# ipro7 register map
Vendor: intelpro; Series: BTBLE
CPU: ipro7, little endian
Registers are 32-bit, read-write, reset 0x0 unless marked. A register's access mark holds for its fields unless they carry their own. Offsets are from the block's base; [hi:lo] are bit positions; {n}, {i} and the like mark numbered series.

## M154_MEM
Base 0x3C000000
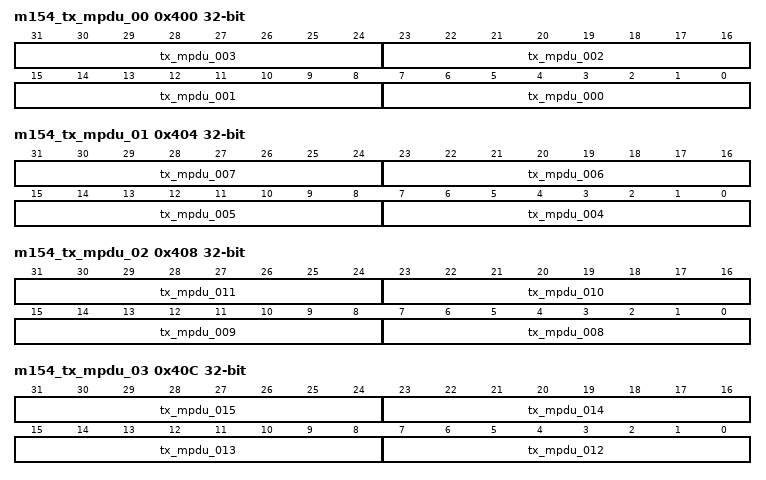
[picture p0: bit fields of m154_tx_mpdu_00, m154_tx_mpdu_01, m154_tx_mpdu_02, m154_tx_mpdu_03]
0x400 m154_tx_mpdu_00 reset not defined
  [8n+7:8n] tx_mpdu_{n:03} ro (n=0..3) — TX MPDU {n}
0x404 m154_tx_mpdu_01 reset not defined
  [8n-25:8n-32] tx_mpdu_{n:03} ro (n=4..7) — TX MPDU {n}
0x408 m154_tx_mpdu_02 reset not defined
  [8n-57:8n-64] tx_mpdu_{n:03} ro (n=8..11) — TX MPDU {n}
0x40C m154_tx_mpdu_03 reset not defined
  [8n-89:8n-96] tx_mpdu_{n:03} ro (n=12..15) — TX MPDU {n}
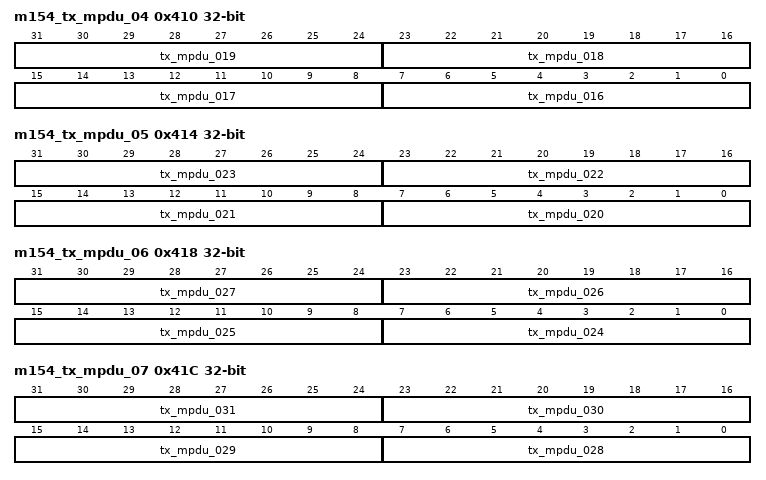
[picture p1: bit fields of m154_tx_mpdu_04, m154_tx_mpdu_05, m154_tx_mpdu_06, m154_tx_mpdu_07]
0x410 m154_tx_mpdu_04 reset not defined
  [8n-121:8n-128] tx_mpdu_{n:03} ro (n=16..19) — TX MPDU {n}
0x414 m154_tx_mpdu_05 reset not defined
  [8n-153:8n-160] tx_mpdu_{n:03} ro (n=20..23) — TX MPDU {n}
0x418 m154_tx_mpdu_06 reset not defined
  [8n-185:8n-192] tx_mpdu_{n:03} ro (n=24..27) — TX MPDU {n}
0x41C m154_tx_mpdu_07 reset not defined
  [8n-217:8n-224] tx_mpdu_{n:03} ro (n=28..31) — TX MPDU {n}
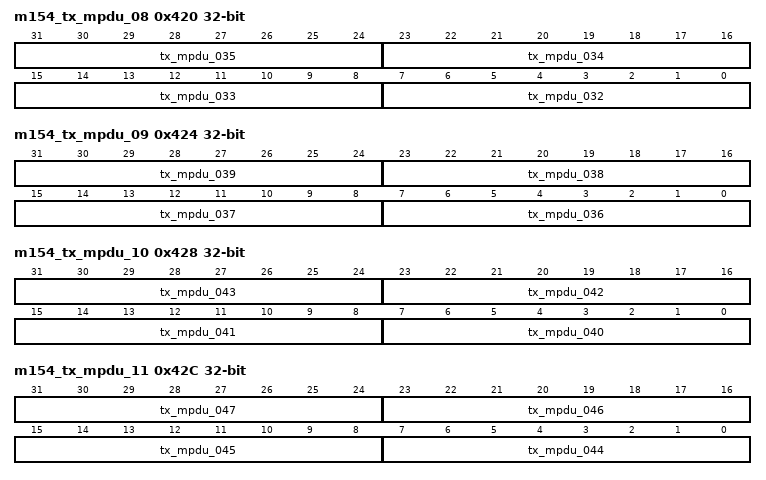
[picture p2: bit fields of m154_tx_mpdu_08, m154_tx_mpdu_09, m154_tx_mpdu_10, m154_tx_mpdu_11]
0x420 m154_tx_mpdu_08 reset not defined
  [8n-249:8n-256] tx_mpdu_{n:03} ro (n=32..35) — TX MPDU {n}
0x424 m154_tx_mpdu_09 reset not defined
  [8n-281:8n-288] tx_mpdu_{n:03} ro (n=36..39) — TX MPDU {n}
0x428 m154_tx_mpdu_10 reset not defined
  [8n-313:8n-320] tx_mpdu_{n:03} ro (n=40..43) — TX MPDU {n}
0x42C m154_tx_mpdu_11 reset not defined
  [8n-345:8n-352] tx_mpdu_{n:03} ro (n=44..47) — TX MPDU {n}
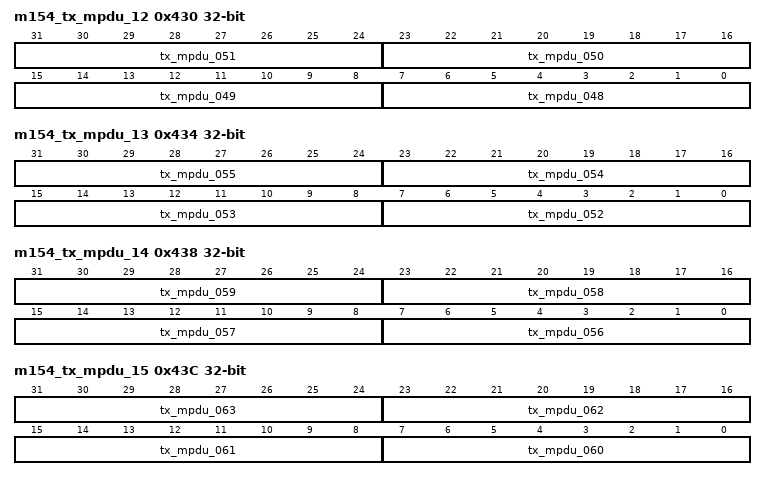
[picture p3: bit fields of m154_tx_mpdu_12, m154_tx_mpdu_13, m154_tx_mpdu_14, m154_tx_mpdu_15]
0x430 m154_tx_mpdu_12 reset not defined
  [8n-377:8n-384] tx_mpdu_{n:03} ro (n=48..51) — TX MPDU {n}
0x434 m154_tx_mpdu_13 reset not defined
  [8n-409:8n-416] tx_mpdu_{n:03} ro (n=52..55) — TX MPDU {n}
0x438 m154_tx_mpdu_14 reset not defined
  [8n-441:8n-448] tx_mpdu_{n:03} ro (n=56..59) — TX MPDU {n}
0x43C m154_tx_mpdu_15 reset not defined
  [8n-473:8n-480] tx_mpdu_{n:03} ro (n=60..63) — TX MPDU {n}
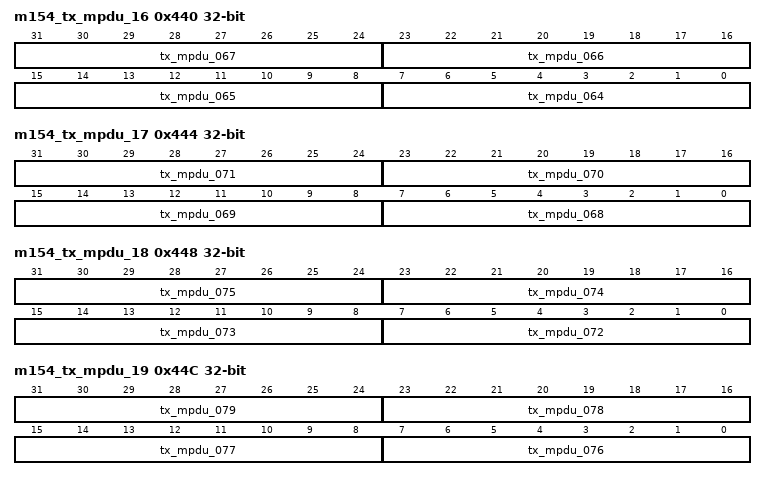
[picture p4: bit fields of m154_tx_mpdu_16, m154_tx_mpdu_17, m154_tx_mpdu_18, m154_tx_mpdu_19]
0x440 m154_tx_mpdu_16 reset not defined
  [8n-505:8n-512] tx_mpdu_{n:03} ro (n=64..67) — TX MPDU {n}
0x444 m154_tx_mpdu_17 reset not defined
  [8n-537:8n-544] tx_mpdu_{n:03} ro (n=68..71) — TX MPDU {n}
0x448 m154_tx_mpdu_18 reset not defined
  [8n-569:8n-576] tx_mpdu_{n:03} ro (n=72..75) — TX MPDU {n}
0x44C m154_tx_mpdu_19 reset not defined
  [8n-601:8n-608] tx_mpdu_{n:03} ro (n=76..79) — TX MPDU {n}
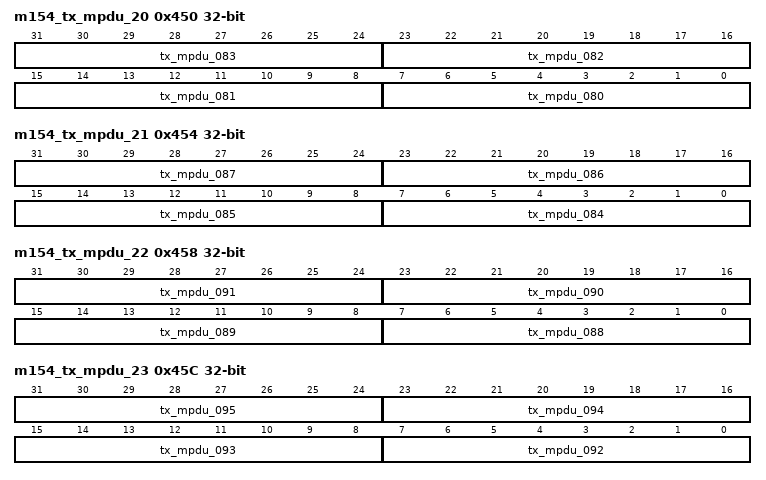
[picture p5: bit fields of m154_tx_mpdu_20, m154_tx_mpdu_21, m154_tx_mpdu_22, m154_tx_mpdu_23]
0x450 m154_tx_mpdu_20 reset not defined
  [8n-633:8n-640] tx_mpdu_{n:03} ro (n=80..83) — TX MPDU {n}
0x454 m154_tx_mpdu_21 reset not defined
  [8n-665:8n-672] tx_mpdu_{n:03} ro (n=84..87) — TX MPDU {n}
0x458 m154_tx_mpdu_22 reset not defined
  [8n-697:8n-704] tx_mpdu_{n:03} ro (n=88..91) — TX MPDU {n}
0x45C m154_tx_mpdu_23 reset not defined
  [8n-729:8n-736] tx_mpdu_{n:03} ro (n=92..95) — TX MPDU {n}
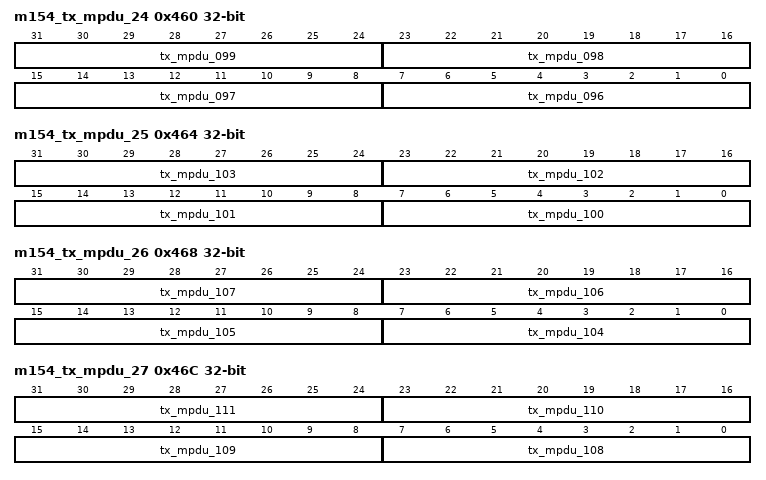
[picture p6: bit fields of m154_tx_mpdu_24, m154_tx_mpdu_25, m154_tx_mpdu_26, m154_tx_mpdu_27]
0x460 m154_tx_mpdu_24 reset not defined
  [8n-761:8n-768] tx_mpdu_{n:03} ro (n=96..99) — TX MPDU {n}
0x464 m154_tx_mpdu_25 reset not defined
  [8n-793:8n-800] tx_mpdu_{n} ro (n=100..103)
0x468 m154_tx_mpdu_26 reset not defined
  [8n-825:8n-832] tx_mpdu_{n} ro (n=104..107)
0x46C m154_tx_mpdu_27 reset not defined
  [8n-857:8n-864] tx_mpdu_{n} ro (n=108..111)
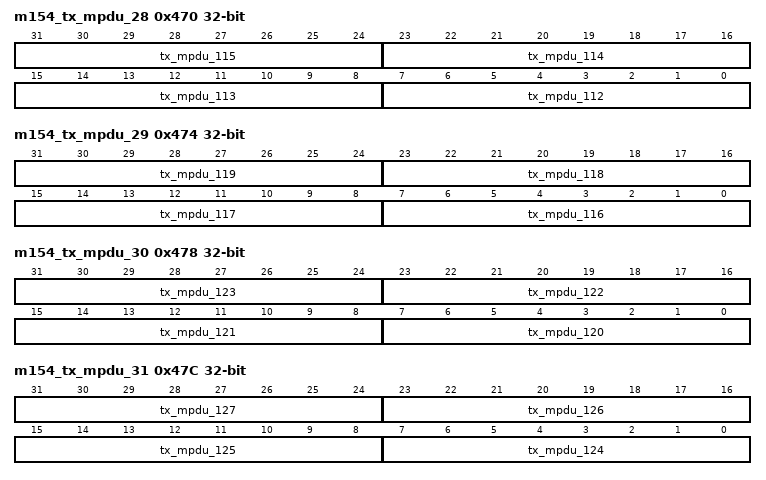
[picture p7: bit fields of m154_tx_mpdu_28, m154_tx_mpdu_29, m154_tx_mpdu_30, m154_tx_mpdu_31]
0x470 m154_tx_mpdu_28 reset not defined
  [8n-889:8n-896] tx_mpdu_{n} ro (n=112..115)
0x474 m154_tx_mpdu_29 reset not defined
  [8n-921:8n-928] tx_mpdu_{n} ro (n=116..119)
0x478 m154_tx_mpdu_30 reset not defined
  [8n-953:8n-960] tx_mpdu_{n} ro (n=120..123)
0x47C m154_tx_mpdu_31 reset not defined
  [8n-985:8n-992] tx_mpdu_{n} ro (n=124..127)
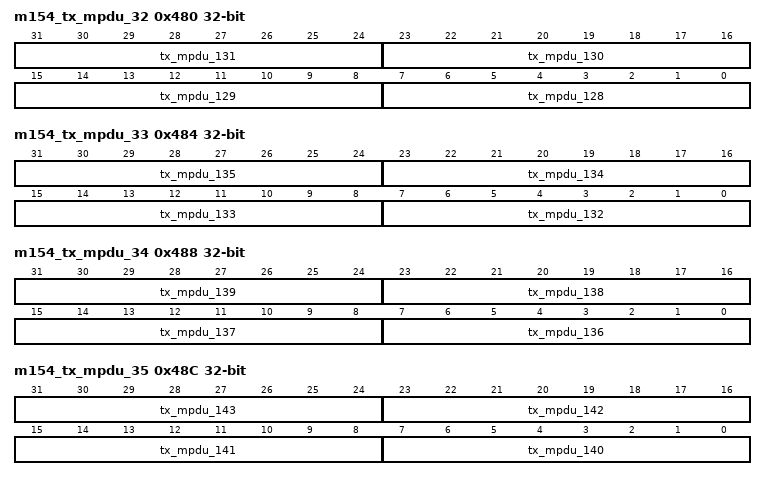
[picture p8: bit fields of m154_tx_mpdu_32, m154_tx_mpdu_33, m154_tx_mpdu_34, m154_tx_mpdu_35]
0x480 m154_tx_mpdu_32 reset not defined
  [8n-1017:8n-1024] tx_mpdu_{n} ro (n=128..131)
0x484 m154_tx_mpdu_33 reset not defined
  [8n-1049:8n-1056] tx_mpdu_{n} ro (n=132..135)
0x488 m154_tx_mpdu_34 reset not defined
  [8n-1081:8n-1088] tx_mpdu_{n} ro (n=136..139)
0x48C m154_tx_mpdu_35 reset not defined
  [8n-1113:8n-1120] tx_mpdu_{n} ro (n=140..143)
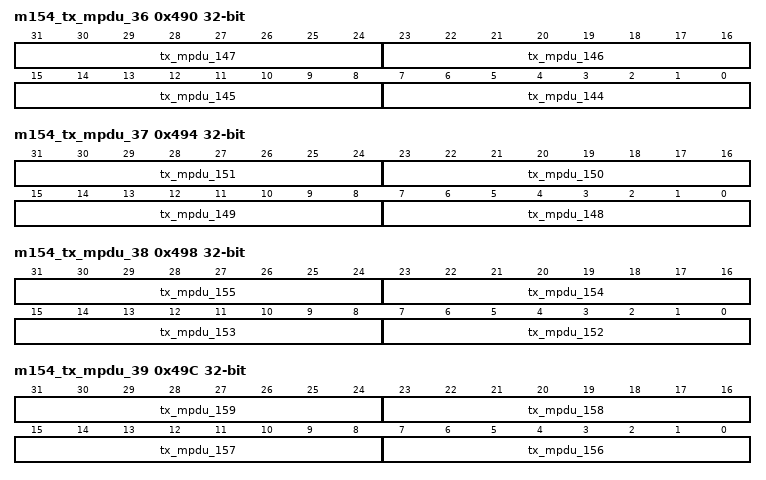
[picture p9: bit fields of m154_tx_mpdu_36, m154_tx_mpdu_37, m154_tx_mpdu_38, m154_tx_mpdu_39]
0x490 m154_tx_mpdu_36 reset not defined
  [8n-1145:8n-1152] tx_mpdu_{n} ro (n=144..147)
0x494 m154_tx_mpdu_37 reset not defined
  [8n-1177:8n-1184] tx_mpdu_{n} ro (n=148..151)
0x498 m154_tx_mpdu_38 reset not defined
  [8n-1209:8n-1216] tx_mpdu_{n} ro (n=152..155)
0x49C m154_tx_mpdu_39 reset not defined
  [8n-1241:8n-1248] tx_mpdu_{n} ro (n=156..159)
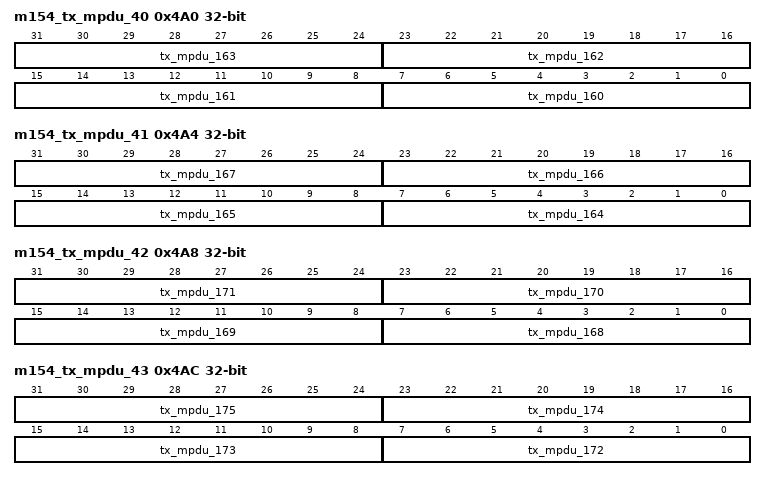
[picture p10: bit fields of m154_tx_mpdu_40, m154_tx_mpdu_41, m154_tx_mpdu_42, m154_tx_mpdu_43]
0x4A0 m154_tx_mpdu_40 reset not defined
  [8n-1273:8n-1280] tx_mpdu_{n} ro (n=160..163)
0x4A4 m154_tx_mpdu_41 reset not defined
  [8n-1305:8n-1312] tx_mpdu_{n} ro (n=164..167)
0x4A8 m154_tx_mpdu_42 reset not defined
  [8n-1337:8n-1344] tx_mpdu_{n} ro (n=168..171)
0x4AC m154_tx_mpdu_43 reset not defined
  [8n-1369:8n-1376] tx_mpdu_{n} ro (n=172..175)
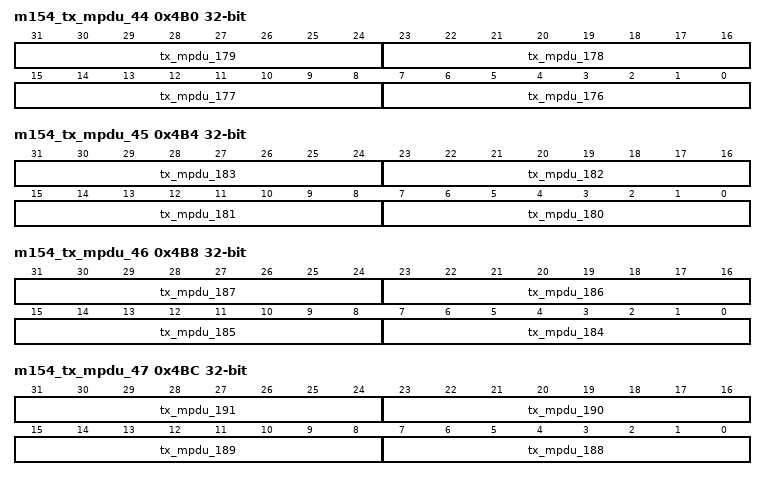
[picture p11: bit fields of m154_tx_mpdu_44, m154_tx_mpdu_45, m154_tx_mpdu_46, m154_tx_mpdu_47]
0x4B0 m154_tx_mpdu_44 reset not defined
  [8n-1401:8n-1408] tx_mpdu_{n} ro (n=176..179)
0x4B4 m154_tx_mpdu_45 reset not defined
  [8n-1433:8n-1440] tx_mpdu_{n} ro (n=180..183)
0x4B8 m154_tx_mpdu_46 reset not defined
  [8n-1465:8n-1472] tx_mpdu_{n} ro (n=184..187)
0x4BC m154_tx_mpdu_47 reset not defined
  [8n-1497:8n-1504] tx_mpdu_{n} ro (n=188..191)
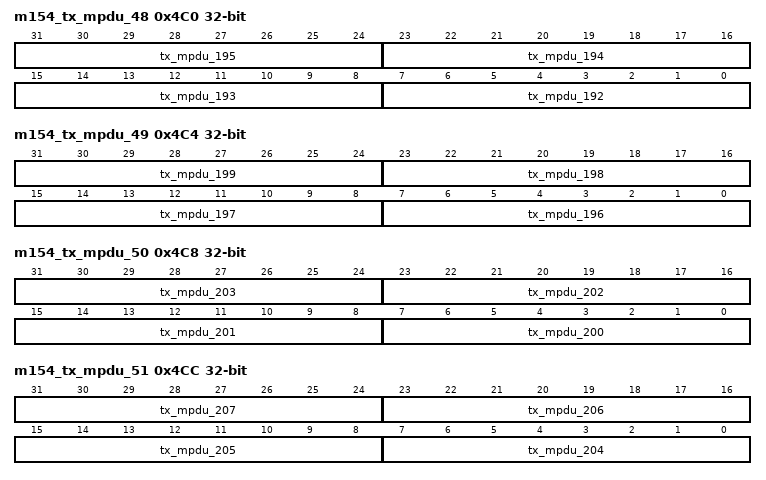
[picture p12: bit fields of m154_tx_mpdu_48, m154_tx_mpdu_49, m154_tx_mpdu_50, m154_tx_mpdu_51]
0x4C0 m154_tx_mpdu_48 reset not defined
  [8n-1529:8n-1536] tx_mpdu_{n} ro (n=192..195)
0x4C4 m154_tx_mpdu_49 reset not defined
  [8n-1561:8n-1568] tx_mpdu_{n} ro (n=196..199)
0x4C8 m154_tx_mpdu_50 reset not defined
  [8n-1593:8n-1600] tx_mpdu_{n} ro (n=200..203)
0x4CC m154_tx_mpdu_51 reset not defined
  [8n-1625:8n-1632] tx_mpdu_{n} ro (n=204..207)
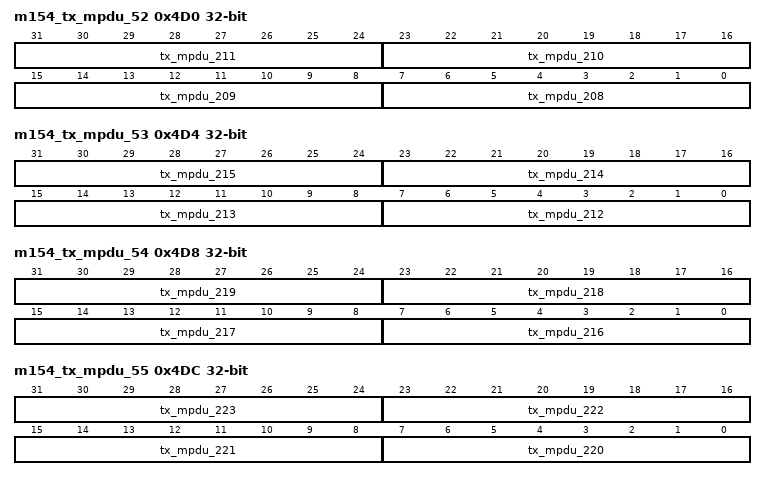
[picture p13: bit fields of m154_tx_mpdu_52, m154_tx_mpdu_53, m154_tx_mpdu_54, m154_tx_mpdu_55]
0x4D0 m154_tx_mpdu_52 reset not defined
  [8n-1657:8n-1664] tx_mpdu_{n} ro (n=208..211)
0x4D4 m154_tx_mpdu_53 reset not defined
  [8n-1689:8n-1696] tx_mpdu_{n} ro (n=212..215)
0x4D8 m154_tx_mpdu_54 reset not defined
  [8n-1721:8n-1728] tx_mpdu_{n} ro (n=216..219)
0x4DC m154_tx_mpdu_55 reset not defined
  [8n-1753:8n-1760] tx_mpdu_{n} ro (n=220..223)
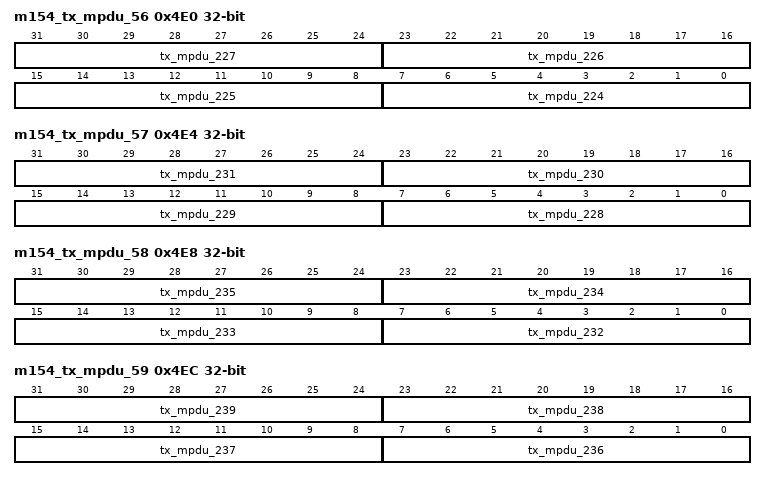
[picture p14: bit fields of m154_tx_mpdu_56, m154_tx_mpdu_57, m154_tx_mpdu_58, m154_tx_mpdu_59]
0x4E0 m154_tx_mpdu_56 reset not defined
  [8n-1785:8n-1792] tx_mpdu_{n} ro (n=224..227)
0x4E4 m154_tx_mpdu_57 reset not defined
  [8n-1817:8n-1824] tx_mpdu_{n} ro (n=228..231)
0x4E8 m154_tx_mpdu_58 reset not defined
  [8n-1849:8n-1856] tx_mpdu_{n} ro (n=232..235)
0x4EC m154_tx_mpdu_59 reset not defined
  [8n-1881:8n-1888] tx_mpdu_{n} ro (n=236..239)
0x4F0 m154_tx_mpdu_60 reset not defined
  [8n-1913:8n-1920] tx_mpdu_{n} ro (n=240..243)
0x4F4 m154_tx_mpdu_61 reset not defined
  [8n-1945:8n-1952] tx_mpdu_{n} ro (n=244..247)
0x4F8 m154_tx_mpdu_62 reset not defined
  [8n-1977:8n-1984] tx_mpdu_{n} ro (n=248..251)
0x4FC m154_tx_mpdu_63 (reset mask 0xFFFFFF00)
  [7:0] tx_mpdu_252 ro
0x500 m154_rx_mpdu_00 reset not defined
  [8n+7:8n] rx_mpdu_{n:03} ro (n=0..3) — RX MPDU {n}
0x504 m154_rx_mpdu_01 reset not defined
  [8n-25:8n-32] rx_mpdu_{n:03} ro (n=4..7) — RX MPDU {n}
0x508 m154_rx_mpdu_02 reset not defined
  [8n-57:8n-64] rx_mpdu_{n:03} ro (n=8..11) — RX MPDU {n}
0x50C m154_rx_mpdu_03 reset not defined
  [8n-89:8n-96] rx_mpdu_{n:03} ro (n=12..15) — RX MPDU {n}
0x510 m154_rx_mpdu_04 reset not defined
  [8n-121:8n-128] rx_mpdu_{n:03} ro (n=16..19) — RX MPDU {n}
0x514 m154_rx_mpdu_05 reset not defined
  [8n-153:8n-160] rx_mpdu_{n:03} ro (n=20..23) — RX MPDU {n}
0x518 m154_rx_mpdu_06 reset not defined
  [8n-185:8n-192] rx_mpdu_{n:03} ro (n=24..27) — RX MPDU {n}
0x51C m154_rx_mpdu_07 reset not defined
  [8n-217:8n-224] rx_mpdu_{n:03} ro (n=28..31) — RX MPDU {n}
0x520 m154_rx_mpdu_08 reset not defined
  [8n-249:8n-256] rx_mpdu_{n:03} ro (n=32..35) — RX MPDU {n}
0x524 m154_rx_mpdu_09 reset not defined
  [8n-281:8n-288] rx_mpdu_{n:03} ro (n=36..39) — RX MPDU {n}
0x528 m154_rx_mpdu_10 reset not defined
  [8n-313:8n-320] rx_mpdu_{n:03} ro (n=40..43) — RX MPDU {n}
0x52C m154_rx_mpdu_11 reset not defined
  [8n-345:8n-352] rx_mpdu_{n:03} ro (n=44..47) — RX MPDU {n}
0x530 m154_rx_mpdu_12 reset not defined
  [8n-377:8n-384] rx_mpdu_{n:03} ro (n=48..51) — RX MPDU {n}
0x534 m154_rx_mpdu_13 reset not defined
  [8n-409:8n-416] rx_mpdu_{n:03} ro (n=52..55) — RX MPDU {n}
0x538 m154_rx_mpdu_14 reset not defined
  [8n-441:8n-448] rx_mpdu_{n:03} ro (n=56..59) — RX MPDU {n}
0x53C m154_rx_mpdu_15 reset not defined
  [8n-473:8n-480] rx_mpdu_{n:03} ro (n=60..63) — RX MPDU {n}
0x540 m154_rx_mpdu_16 reset not defined
  [8n-505:8n-512] rx_mpdu_{n:03} ro (n=64..67) — RX MPDU {n}
0x544 m154_rx_mpdu_17 reset not defined
  [8n-537:8n-544] rx_mpdu_{n:03} ro (n=68..71) — RX MPDU {n}
0x548 m154_rx_mpdu_18 reset not defined
  [8n-569:8n-576] rx_mpdu_{n:03} ro (n=72..75) — RX MPDU {n}
0x54C m154_rx_mpdu_19 reset not defined
  [8n-601:8n-608] rx_mpdu_{n:03} ro (n=76..79) — RX MPDU {n}
0x550 m154_rx_mpdu_20 reset not defined
  [8n-633:8n-640] rx_mpdu_{n:03} ro (n=80..83) — RX MPDU {n}
0x554 m154_rx_mpdu_21 reset not defined
  [8n-665:8n-672] rx_mpdu_{n:03} ro (n=84..87) — RX MPDU {n}
0x558 m154_rx_mpdu_22 reset not defined
  [8n-697:8n-704] rx_mpdu_{n:03} ro (n=88..91) — RX MPDU {n}
0x55C m154_rx_mpdu_23 reset not defined
  [8n-729:8n-736] rx_mpdu_{n:03} ro (n=92..95) — RX MPDU {n}
0x560 m154_rx_mpdu_24 reset not defined
  [8n-761:8n-768] rx_mpdu_{n:03} ro (n=96..99) — RX MPDU {n}
0x564 m154_rx_mpdu_25 reset not defined
  [8n-793:8n-800] rx_mpdu_{n} ro (n=100..103)
0x568 m154_rx_mpdu_26 reset not defined
  [8n-825:8n-832] rx_mpdu_{n} ro (n=104..107)
0x56C m154_rx_mpdu_27 reset not defined
  [8n-857:8n-864] rx_mpdu_{n} ro (n=108..111)
0x570 m154_rx_mpdu_28 reset not defined
  [8n-889:8n-896] rx_mpdu_{n} ro (n=112..115)
0x574 m154_rx_mpdu_29 reset not defined
  [8n-921:8n-928] rx_mpdu_{n} ro (n=116..119)
0x578 m154_rx_mpdu_30 reset not defined
  [8n-953:8n-960] rx_mpdu_{n} ro (n=120..123)
0x57C m154_rx_mpdu_31 reset not defined
  [8n-985:8n-992] rx_mpdu_{n} ro (n=124..127)
0x580 m154_rx_mpdu_32 reset not defined
  [8n-1017:8n-1024] rx_mpdu_{n} ro (n=128..131)
0x584 m154_rx_mpdu_33 reset not defined
  [8n-1049:8n-1056] rx_mpdu_{n} ro (n=132..135)
0x588 m154_rx_mpdu_34 reset not defined
  [8n-1081:8n-1088] rx_mpdu_{n} ro (n=136..139)
0x58C m154_rx_mpdu_35 reset not defined
  [8n-1113:8n-1120] rx_mpdu_{n} ro (n=140..143)
0x590 m154_rx_mpdu_36 reset not defined
  [8n-1145:8n-1152] rx_mpdu_{n} ro (n=144..147)
0x594 m154_rx_mpdu_37 reset not defined
  [8n-1177:8n-1184] rx_mpdu_{n} ro (n=148..151)
0x598 m154_rx_mpdu_38 reset not defined
  [8n-1209:8n-1216] rx_mpdu_{n} ro (n=152..155)
0x59C m154_rx_mpdu_39 reset not defined
  [8n-1241:8n-1248] rx_mpdu_{n} ro (n=156..159)
0x5A0 m154_rx_mpdu_40 reset not defined
  [8n-1273:8n-1280] rx_mpdu_{n} ro (n=160..163)
0x5A4 m154_rx_mpdu_41 reset not defined
  [8n-1305:8n-1312] rx_mpdu_{n} ro (n=164..167)
0x5A8 m154_rx_mpdu_42 reset not defined
  [8n-1337:8n-1344] rx_mpdu_{n} ro (n=168..171)
0x5AC m154_rx_mpdu_43 reset not defined
  [8n-1369:8n-1376] rx_mpdu_{n} ro (n=172..175)
0x5B0 m154_rx_mpdu_44 reset not defined
  [8n-1401:8n-1408] rx_mpdu_{n} ro (n=176..179)
0x5B4 m154_rx_mpdu_45 reset not defined
  [8n-1433:8n-1440] rx_mpdu_{n} ro (n=180..183)
0x5B8 m154_rx_mpdu_46 reset not defined
  [8n-1465:8n-1472] rx_mpdu_{n} ro (n=184..187)
0x5BC m154_rx_mpdu_47 reset not defined
  [8n-1497:8n-1504] rx_mpdu_{n} ro (n=188..191)
0x5C0 m154_rx_mpdu_48 reset not defined
  [8n-1529:8n-1536] rx_mpdu_{n} ro (n=192..195)
0x5C4 m154_rx_mpdu_49 reset not defined
  [8n-1561:8n-1568] rx_mpdu_{n} ro (n=196..199)
0x5C8 m154_rx_mpdu_50 reset not defined
  [8n-1593:8n-1600] rx_mpdu_{n} ro (n=200..203)
0x5CC m154_rx_mpdu_51 reset not defined
  [8n-1625:8n-1632] rx_mpdu_{n} ro (n=204..207)
0x5D0 m154_rx_mpdu_52 reset not defined
  [8n-1657:8n-1664] rx_mpdu_{n} ro (n=208..211)
0x5D4 m154_rx_mpdu_53 reset not defined
  [8n-1689:8n-1696] rx_mpdu_{n} ro (n=212..215)
0x5D8 m154_rx_mpdu_54 reset not defined
  [8n-1721:8n-1728] rx_mpdu_{n} ro (n=216..219)
0x5DC m154_rx_mpdu_55 reset not defined
  [8n-1753:8n-1760] rx_mpdu_{n} ro (n=220..223)
0x5E0 m154_rx_mpdu_56 reset not defined
  [8n-1785:8n-1792] rx_mpdu_{n} ro (n=224..227)
0x5E4 m154_rx_mpdu_57 reset not defined
  [8n-1817:8n-1824] rx_mpdu_{n} ro (n=228..231)
0x5E8 m154_rx_mpdu_58 reset not defined
  [8n-1849:8n-1856] rx_mpdu_{n} ro (n=232..235)
0x5EC m154_rx_mpdu_59 reset not defined
  [8n-1881:8n-1888] rx_mpdu_{n} ro (n=236..239)
0x5F0 m154_rx_mpdu_60 reset not defined
  [8n-1913:8n-1920] rx_mpdu_{n} ro (n=240..243)
0x5F4 m154_rx_mpdu_61 reset not defined
  [8n-1945:8n-1952] rx_mpdu_{n} ro (n=244..247)
0x5F8 m154_rx_mpdu_62 reset not defined
  [8n-1977:8n-1984] rx_mpdu_{n} ro (n=248..251)
0x5FC m154_rx_mpdu_63 (reset mask 0xFFFFFF00)
  [7:0] rx_mpdu_252 ro
{0x600+4i} m154_nbr_{i:03} (i=0..3)
  [18] nbr_valid_{i:03} — Valid tags of the entry. Bit is 1 if address in the entry is valid. Otherwise, bit is 0.
  [17] nbr_ext_addr_mode_{i:03} — Extended address mode of the entry. Bit is 1 if address in the entry is part of extended address. Otherwise, bit is 0.
  [16] nbr_fp_{i:03} — Frame pending bit of the entry. Bit is 1 if there is data frame pending for the device. Otherwise, bit is 0.
  [15:0] nbr_addr_{i:03} — If nbr_ext_addr_mode_000 is 1, this 16-bit address is bit {16i+15}~{16i} of extended address. Otherwise, this 16-bit address is a short address.
{0x600+4i} m154_nbr_{i:03} (i=4..7)
  [18] nbr_valid_{i:03} — Valid tags of the entry. Bit is 1 if address in the entry is valid. Otherwise, bit is 0.
  [17] nbr_ext_addr_mode_{i:03} — Extended address mode of the entry. Bit is 1 if address in the entry is part of extended address. Otherwise, bit is 0.
  [16] nbr_fp_{i:03} — Frame pending bit of the entry. Bit is 1 if there is data frame pending for the device. Otherwise, bit is 0.
  [15:0] nbr_addr_{i:03} — If nbr_ext_addr_mode_004 is 1, this 16-bit address is bit {16i-49}~{16i-64} of extended address. Otherwise, this 16-bit address is a short address.
{0x600+4i} m154_nbr_{i:03} (i=8..11)
  [18] nbr_valid_{i:03} — Valid tags of the entry. Bit is 1 if address in the entry is valid. Otherwise, bit is 0.
  [17] nbr_ext_addr_mode_{i:03} — Extended address mode of the entry. Bit is 1 if address in the entry is part of extended address. Otherwise, bit is 0.
  [16] nbr_fp_{i:03} — Frame pending bit of the entry. Bit is 1 if there is data frame pending for the device. Otherwise, bit is 0.
  [15:0] nbr_addr_{i:03} — If nbr_ext_addr_mode_008 is 1, this 16-bit address is bit {16i-113}~{16i-128} of extended address. Otherwise, this 16-bit address is a short address.
{0x600+4i} m154_nbr_{i:03} (i=12..15)
  [18] nbr_valid_{i:03} — Valid tags of the entry. Bit is 1 if address in the entry is valid. Otherwise, bit is 0.
  [17] nbr_ext_addr_mode_{i:03} — Extended address mode of the entry. Bit is 1 if address in the entry is part of extended address. Otherwise, bit is 0.
  [16] nbr_fp_{i:03} — Frame pending bit of the entry. Bit is 1 if there is data frame pending for the device. Otherwise, bit is 0.
  [15:0] nbr_addr_{i:03} — If nbr_ext_addr_mode_012 is 1, this 16-bit address is bit {16i-177}~{16i-192} of extended address. Otherwise, this 16-bit address is a short address.
{0x600+4i} m154_nbr_{i:03} (i=16..19)
  [18] nbr_valid_{i:03} — Valid tags of the entry. Bit is 1 if address in the entry is valid. Otherwise, bit is 0.
  [17] nbr_ext_addr_mode_{i:03} — Extended address mode of the entry. Bit is 1 if address in the entry is part of extended address. Otherwise, bit is 0.
  [16] nbr_fp_{i:03} — Frame pending bit of the entry. Bit is 1 if there is data frame pending for the device. Otherwise, bit is 0.
  [15:0] nbr_addr_{i:03} — If nbr_ext_addr_mode_016 is 1, this 16-bit address is bit {16i-241}~{16i-256} of extended address. Otherwise, this 16-bit address is a short address.
0x650 m154_nbr_020
  [18] nbr_valid_020 — Valid tags of the entry. Bit is 1 if address in the entry is valid. Otherwise, bit is 0.
  [17] nbr_ext_addr_mode_020 — Extended address mode of the entry. Bit is 1 if address in the entry is part of extended address. Otherwise, bit is 0.
  [16] nbr_fp_020 — Frame pending bit of the entry. Bit is 1 if there is data frame pending for the device. Otherwise, bit is 0.
  [15:0] nbr_addr_020 — If nbr_ext_addr_mode_020 is 1, this 16-bit address is bit 15~0 of extended address. Otherwise, this 16-bit address is a short address.
{0x600+4i} m154_nbr_{i:03} (i=21..23)
  [18] nbr_valid_{i:03} — Valid tags of the entry. Bit is 1 if address in the entry is valid. Otherwise, bit is 0.
  [17] nbr_ext_addr_mode_{i:03} — Extended address mode of the entry. Bit is 1 if address in the entry is part of extended address. Otherwise, bit is 0.
  [16] nbr_fp_{i:03} — Frame pending bit of the entry. Bit is 1 if there is data frame pending for the device. Otherwise, bit is 0.
  [15:0] nbr_addr_{i:03} — If nbr_ext_addr_mode_021 is 1, this 16-bit address is bit {16i-305}~{16i-320} of extended address. Otherwise, this 16-bit address is a short address.
{0x600+4i} m154_nbr_{i:03} (i=24..27)
  [18] nbr_valid_{i:03} — Valid tags of the entry. Bit is 1 if address in the entry is valid. Otherwise, bit is 0.
  [17] nbr_ext_addr_mode_{i:03} — Extended address mode of the entry. Bit is 1 if address in the entry is part of extended address. Otherwise, bit is 0.
  [16] nbr_fp_{i:03} — Frame pending bit of the entry. Bit is 1 if there is data frame pending for the device. Otherwise, bit is 0.
  [15:0] nbr_addr_{i:03} — If nbr_ext_addr_mode_024 is 1, this 16-bit address is bit {16i-369}~{16i-384} of extended address. Otherwise, this 16-bit address is a short address.
{0x600+4i} m154_nbr_{i:03} (i=28..31)
  [18] nbr_valid_{i:03} — Valid tags of the entry. Bit is 1 if address in the entry is valid. Otherwise, bit is 0.
  [17] nbr_ext_addr_mode_{i:03} — Extended address mode of the entry. Bit is 1 if address in the entry is part of extended address. Otherwise, bit is 0.
  [16] nbr_fp_{i:03} — Frame pending bit of the entry. Bit is 1 if there is data frame pending for the device. Otherwise, bit is 0.
  [15:0] nbr_addr_{i:03} — If nbr_ext_addr_mode_028 is 1, this 16-bit address is bit {16i-433}~{16i-448} of extended address. Otherwise, this 16-bit address is a short address.
{0x600+4i} m154_nbr_{i:03} (i=32..35)
  [18] nbr_valid_{i:03} — Valid tags of the entry. Bit is 1 if address in the entry is valid. Otherwise, bit is 0.
  [17] nbr_ext_addr_mode_{i:03} — Extended address mode of the entry. Bit is 1 if address in the entry is part of extended address. Otherwise, bit is 0.
  [16] nbr_fp_{i:03} — Frame pending bit of the entry. Bit is 1 if there is data frame pending for the device. Otherwise, bit is 0.
  [15:0] nbr_addr_{i:03} — If nbr_ext_addr_mode_032 is 1, this 16-bit address is bit {16i-497}~{16i-512} of extended address. Otherwise, this 16-bit address is a short address.
{0x600+4i} m154_nbr_{i:03} (i=36..39)
  [18] nbr_valid_{i:03} — Valid tags of the entry. Bit is 1 if address in the entry is valid. Otherwise, bit is 0.
  [17] nbr_ext_addr_mode_{i:03} — Extended address mode of the entry. Bit is 1 if address in the entry is part of extended address. Otherwise, bit is 0.
  [16] nbr_fp_{i:03} — Frame pending bit of the entry. Bit is 1 if there is data frame pending for the device. Otherwise, bit is 0.
  [15:0] nbr_addr_{i:03} — If nbr_ext_addr_mode_036 is 1, this 16-bit address is bit {16i-561}~{16i-576} of extended address. Otherwise, this 16-bit address is a short address.
{0x600+4i} m154_nbr_{i:03} (i=40..43)
  [18] nbr_valid_{i:03} — Valid tags of the entry. Bit is 1 if address in the entry is valid. Otherwise, bit is 0.
  [17] nbr_ext_addr_mode_{i:03} — Extended address mode of the entry. Bit is 1 if address in the entry is part of extended address. Otherwise, bit is 0.
  [16] nbr_fp_{i:03} — Frame pending bit of the entry. Bit is 1 if there is data frame pending for the device. Otherwise, bit is 0.
  [15:0] nbr_addr_{i:03} — If nbr_ext_addr_mode_040 is 1, this 16-bit address is bit {16i-625}~{16i-640} of extended address. Otherwise, this 16-bit address is a short address.
{0x600+4i} m154_nbr_{i:03} (i=44..47)
  [18] nbr_valid_{i:03} — Valid tags of the entry. Bit is 1 if address in the entry is valid. Otherwise, bit is 0.
  [17] nbr_ext_addr_mode_{i:03} — Extended address mode of the entry. Bit is 1 if address in the entry is part of extended address. Otherwise, bit is 0.
  [16] nbr_fp_{i:03} — Frame pending bit of the entry. Bit is 1 if there is data frame pending for the device. Otherwise, bit is 0.
  [15:0] nbr_addr_{i:03} — If nbr_ext_addr_mode_044 is 1, this 16-bit address is bit {16i-689}~{16i-704} of extended address. Otherwise, this 16-bit address is a short address.
{0x600+4i} m154_nbr_{i:03} (i=48..51)
  [18] nbr_valid_{i:03} — Valid tags of the entry. Bit is 1 if address in the entry is valid. Otherwise, bit is 0.
  [17] nbr_ext_addr_mode_{i:03} — Extended address mode of the entry. Bit is 1 if address in the entry is part of extended address. Otherwise, bit is 0.
  [16] nbr_fp_{i:03} — Frame pending bit of the entry. Bit is 1 if there is data frame pending for the device. Otherwise, bit is 0.
  [15:0] nbr_addr_{i:03} — If nbr_ext_addr_mode_048 is 1, this 16-bit address is bit {16i-753}~{16i-768} of extended address. Otherwise, this 16-bit address is a short address.
{0x600+4i} m154_nbr_{i:03} (i=52..55)
  [18] nbr_valid_{i:03} — Valid tags of the entry. Bit is 1 if address in the entry is valid. Otherwise, bit is 0.
  [17] nbr_ext_addr_mode_{i:03} — Extended address mode of the entry. Bit is 1 if address in the entry is part of extended address. Otherwise, bit is 0.
  [16] nbr_fp_{i:03} — Frame pending bit of the entry. Bit is 1 if there is data frame pending for the device. Otherwise, bit is 0.
  [15:0] nbr_addr_{i:03} — If nbr_ext_addr_mode_052 is 1, this 16-bit address is bit {16i-817}~{16i-832} of extended address. Otherwise, this 16-bit address is a short address.
{0x600+4i} m154_nbr_{i:03} (i=56..59)
  [18] nbr_valid_{i:03} — Valid tags of the entry. Bit is 1 if address in the entry is valid. Otherwise, bit is 0.
  [17] nbr_ext_addr_mode_{i:03} — Extended address mode of the entry. Bit is 1 if address in the entry is part of extended address. Otherwise, bit is 0.
  [16] nbr_fp_{i:03} — Frame pending bit of the entry. Bit is 1 if there is data frame pending for the device. Otherwise, bit is 0.
  [15:0] nbr_addr_{i:03} — If nbr_ext_addr_mode_056 is 1, this 16-bit address is bit {16i-881}~{16i-896} of extended address. Otherwise, this 16-bit address is a short address.
{0x600+4i} m154_nbr_{i:03} (i=60..63)
  [18] nbr_valid_{i:03} — Valid tags of the entry. Bit is 1 if address in the entry is valid. Otherwise, bit is 0.
  [17] nbr_ext_addr_mode_{i:03} — Extended address mode of the entry. Bit is 1 if address in the entry is part of extended address. Otherwise, bit is 0.
  [16] nbr_fp_{i:03} — Frame pending bit of the entry. Bit is 1 if there is data frame pending for the device. Otherwise, bit is 0.
  [15:0] nbr_addr_{i:03} — If nbr_ext_addr_mode_060 is 1, this 16-bit address is bit {16i-945}~{16i-960} of extended address. Otherwise, this 16-bit address is a short address.
{0x600+4i} m154_nbr_{i:03} (i=64..67)
  [18] nbr_valid_{i:03} — Valid tags of the entry. Bit is 1 if address in the entry is valid. Otherwise, bit is 0.
  [17] nbr_ext_addr_mode_{i:03} — Extended address mode of the entry. Bit is 1 if address in the entry is part of extended address. Otherwise, bit is 0.
  [16] nbr_fp_{i:03} — Frame pending bit of the entry. Bit is 1 if there is data frame pending for the device. Otherwise, bit is 0.
  [15:0] nbr_addr_{i:03} — If nbr_ext_addr_mode_064 is 1, this 16-bit address is bit {16i-1009}~{16i-1024} of extended address. Otherwise, this 16-bit address is a short address.
{0x600+4i} m154_nbr_{i:03} (i=68..70)
  [18] nbr_valid_{i:03} — Valid tags of the entry. Bit is 1 if address in the entry is valid. Otherwise, bit is 0.
  [17] nbr_ext_addr_mode_{i:03} — Extended address mode of the entry. Bit is 1 if address in the entry is part of extended address. Otherwise, bit is 0.
  [16] nbr_fp_{i:03} — Frame pending bit of the entry. Bit is 1 if there is data frame pending for the device. Otherwise, bit is 0.
  [15:0] nbr_addr_{i:03} — If nbr_ext_addr_mode_068 is 1, this 16-bit address is bit {16i-1073}~{16i-1088} of extended address. Otherwise, this 16-bit address is a short address.
0x71C m154_nbr_071
  [18] nbr_valid_071 — Valid tags of the entry. Bit is 1 if address in the entry is valid. Otherwise, bit is 0.
  [17] nbr_ext_addr_mode_071 — Extended address mode of the entry. Bit is 1 if address in the entry is part of extended address. Otherwise, bit is 0.
  [16] nbr_fp_072 — Frame pending bit of the entry. Bit is 1 if there is data frame pending for the device. Otherwise, bit is 0.
  [15:0] nbr_addr_073 — If nbr_ext_addr_mode_068 is 1, this 16-bit address is bit 63~48 of extended address. Otherwise, this 16-bit address is a short address.
{0x600+4i} m154_nbr_{i:03} (i=72..75)
  [18] nbr_valid_{i:03} — Valid tags of the entry. Bit is 1 if address in the entry is valid. Otherwise, bit is 0.
  [17] nbr_ext_addr_mode_{i:03} — Extended address mode of the entry. Bit is 1 if address in the entry is part of extended address. Otherwise, bit is 0.
  [16] nbr_fp_{i:03} — Frame pending bit of the entry. Bit is 1 if there is data frame pending for the device. Otherwise, bit is 0.
  [15:0] nbr_addr_{i:03} — If nbr_ext_addr_mode_072 is 1, this 16-bit address is bit {16i-1137}~{16i-1152} of extended address. Otherwise, this 16-bit address is a short address.
{0x600+4i} m154_nbr_{i:03} (i=76..79)
  [18] nbr_valid_{i:03} — Valid tags of the entry. Bit is 1 if address in the entry is valid. Otherwise, bit is 0.
  [17] nbr_ext_addr_mode_{i:03} — Extended address mode of the entry. Bit is 1 if address in the entry is part of extended address. Otherwise, bit is 0.
  [16] nbr_fp_{i:03} — Frame pending bit of the entry. Bit is 1 if there is data frame pending for the device. Otherwise, bit is 0.
  [15:0] nbr_addr_{i:03} — If nbr_ext_addr_mode_076 is 1, this 16-bit address is bit {16i-1201}~{16i-1216} of extended address. Otherwise, this 16-bit address is a short address.
{0x600+4i} m154_nbr_{i:03} (i=80..83)
  [18] nbr_valid_{i:03} — Valid tags of the entry. Bit is 1 if address in the entry is valid. Otherwise, bit is 0.
  [17] nbr_ext_addr_mode_{i:03} — Extended address mode of the entry. Bit is 1 if address in the entry is part of extended address. Otherwise, bit is 0.
  [16] nbr_fp_{i:03} — Frame pending bit of the entry. Bit is 1 if there is data frame pending for the device. Otherwise, bit is 0.
  [15:0] nbr_addr_{i:03} — If nbr_ext_addr_mode_080 is 1, this 16-bit address is bit {16i-1265}~{16i-1280} of extended address. Otherwise, this 16-bit address is a short address.
{0x600+4i} m154_nbr_{i:03} (i=84..87)
  [18] nbr_valid_{i:03} — Valid tags of the entry. Bit is 1 if address in the entry is valid. Otherwise, bit is 0.
  [17] nbr_ext_addr_mode_{i:03} — Extended address mode of the entry. Bit is 1 if address in the entry is part of extended address. Otherwise, bit is 0.
  [16] nbr_fp_{i:03} — Frame pending bit of the entry. Bit is 1 if there is data frame pending for the device. Otherwise, bit is 0.
  [15:0] nbr_addr_{i:03} — If nbr_ext_addr_mode_084 is 1, this 16-bit address is bit {16i-1329}~{16i-1344} of extended address. Otherwise, this 16-bit address is a short address.
{0x600+4i} m154_nbr_{i:03} (i=88..91)
  [18] nbr_valid_{i:03} — Valid tags of the entry. Bit is 1 if address in the entry is valid. Otherwise, bit is 0.
  [17] nbr_ext_addr_mode_{i:03} — Extended address mode of the entry. Bit is 1 if address in the entry is part of extended address. Otherwise, bit is 0.
  [16] nbr_fp_{i:03} — Frame pending bit of the entry. Bit is 1 if there is data frame pending for the device. Otherwise, bit is 0.
  [15:0] nbr_addr_{i:03} — If nbr_ext_addr_mode_088 is 1, this 16-bit address is bit {16i-1393}~{16i-1408} of extended address. Otherwise, this 16-bit address is a short address.
{0x600+4i} m154_nbr_{i:03} (i=92..95)
  [18] nbr_valid_{i:03} — Valid tags of the entry. Bit is 1 if address in the entry is valid. Otherwise, bit is 0.
  [17] nbr_ext_addr_mode_{i:03} — Extended address mode of the entry. Bit is 1 if address in the entry is part of extended address. Otherwise, bit is 0.
  [16] nbr_fp_{i:03} — Frame pending bit of the entry. Bit is 1 if there is data frame pending for the device. Otherwise, bit is 0.
  [15:0] nbr_addr_{i:03} — If nbr_ext_addr_mode_092 is 1, this 16-bit address is bit {16i-1457}~{16i-1472} of extended address. Otherwise, this 16-bit address is a short address.
{0x600+4i} m154_nbr_{i:03} (i=96..99)
  [18] nbr_valid_{i:03} — Valid tags of the entry. Bit is 1 if address in the entry is valid. Otherwise, bit is 0.
  [17] nbr_ext_addr_mode_{i:03} — Extended address mode of the entry. Bit is 1 if address in the entry is part of extended address. Otherwise, bit is 0.
  [16] nbr_fp_{i:03} — Frame pending bit of the entry. Bit is 1 if there is data frame pending for the device. Otherwise, bit is 0.
  [15:0] nbr_addr_{i:03} — If nbr_ext_addr_mode_096 is 1, this 16-bit address is bit {16i-1521}~{16i-1536} of extended address. Otherwise, this 16-bit address is a short address.
{0x600+4i} m154_nbr_{i} (i=100..103)
  [18] nbr_valid_{i} — Valid tags of the entry. Bit is 1 if address in the entry is valid. Otherwise, bit is 0.
  [17] nbr_ext_addr_mode_{i} — Extended address mode of the entry. Bit is 1 if address in the entry is part of extended address. Otherwise, bit is 0.
  [16] nbr_fp_{i} — Frame pending bit of the entry. Bit is 1 if there is data frame pending for the device. Otherwise, bit is 0.
  [15:0] nbr_addr_{i} — If nbr_ext_addr_mode_100 is 1, this 16-bit address is bit {16i-1585}~{16i-1600} of extended address. Otherwise, this 16-bit address is a short address.
{0x600+4i} m154_nbr_{i} (i=104..107)
  [18] nbr_valid_{i} — Valid tags of the entry. Bit is 1 if address in the entry is valid. Otherwise, bit is 0.
  [17] nbr_ext_addr_mode_{i} — Extended address mode of the entry. Bit is 1 if address in the entry is part of extended address. Otherwise, bit is 0.
  [16] nbr_fp_{i} — Frame pending bit of the entry. Bit is 1 if there is data frame pending for the device. Otherwise, bit is 0.
  [15:0] nbr_addr_{i} — If nbr_ext_addr_mode_104 is 1, this 16-bit address is bit {16i-1649}~{16i-1664} of extended address. Otherwise, this 16-bit address is a short address.
{0x600+4i} m154_nbr_{i} (i=108..111)
  [18] nbr_valid_{i} — Valid tags of the entry. Bit is 1 if address in the entry is valid. Otherwise, bit is 0.
  [17] nbr_ext_addr_mode_{i} — Extended address mode of the entry. Bit is 1 if address in the entry is part of extended address. Otherwise, bit is 0.
  [16] nbr_fp_{i} — Frame pending bit of the entry. Bit is 1 if there is data frame pending for the device. Otherwise, bit is 0.
  [15:0] nbr_addr_{i} — If nbr_ext_addr_mode_108 is 1, this 16-bit address is bit {16i-1713}~{16i-1728} of extended address. Otherwise, this 16-bit address is a short address.
{0x600+4i} m154_nbr_{i} (i=112..115)
  [18] nbr_valid_{i} — Valid tags of the entry. Bit is 1 if address in the entry is valid. Otherwise, bit is 0.
  [17] nbr_ext_addr_mode_{i} — Extended address mode of the entry. Bit is 1 if address in the entry is part of extended address. Otherwise, bit is 0.
  [16] nbr_fp_{i} — Frame pending bit of the entry. Bit is 1 if there is data frame pending for the device. Otherwise, bit is 0.
  [15:0] nbr_addr_{i} — If nbr_ext_addr_mode_112 is 1, this 16-bit address is bit {16i-1777}~{16i-1792} of extended address. Otherwise, this 16-bit address is a short address.
{0x600+4i} m154_nbr_{i} (i=116..119)
  [18] nbr_valid_{i} — Valid tags of the entry. Bit is 1 if address in the entry is valid. Otherwise, bit is 0.
  [17] nbr_ext_addr_mode_{i} — Extended address mode of the entry. Bit is 1 if address in the entry is part of extended address. Otherwise, bit is 0.
  [16] nbr_fp_{i} — Frame pending bit of the entry. Bit is 1 if there is data frame pending for the device. Otherwise, bit is 0.
  [15:0] nbr_addr_{i} — If nbr_ext_addr_mode_116 is 1, this 16-bit address is bit {16i-1841}~{16i-1856} of extended address. Otherwise, this 16-bit address is a short address.
{0x600+4i} m154_nbr_{i} (i=120..123)
  [18] nbr_valid_{i} — Valid tags of the entry. Bit is 1 if address in the entry is valid. Otherwise, bit is 0.
  [17] nbr_ext_addr_mode_{i} — Extended address mode of the entry. Bit is 1 if address in the entry is part of extended address. Otherwise, bit is 0.
  [16] nbr_fp_{i} — Frame pending bit of the entry. Bit is 1 if there is data frame pending for the device. Otherwise, bit is 0.
  [15:0] nbr_addr_{i} — If nbr_ext_addr_mode_120 is 1, this 16-bit address is bit {16i-1905}~{16i-1920} of extended address. Otherwise, this 16-bit address is a short address.
{0x600+4i} m154_nbr_{i} (i=124..127)
  [18] nbr_valid_{i} — Valid tags of the entry. Bit is 1 if address in the entry is valid. Otherwise, bit is 0.
  [17] nbr_ext_addr_mode_{i} — Extended address mode of the entry. Bit is 1 if address in the entry is part of extended address. Otherwise, bit is 0.
  [16] nbr_fp_{i} — Frame pending bit of the entry. Bit is 1 if there is data frame pending for the device. Otherwise, bit is 0.
  [15:0] nbr_addr_{i} — If nbr_ext_addr_mode_124 is 1, this 16-bit address is bit {16i-1969}~{16i-1984} of extended address. Otherwise, this 16-bit address is a short address.
